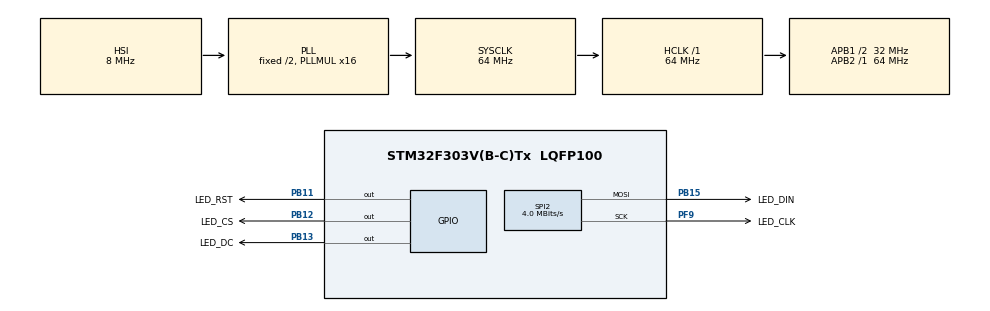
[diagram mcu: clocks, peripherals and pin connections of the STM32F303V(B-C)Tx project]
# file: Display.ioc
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Mcu.Family=STM32F3
Mcu.Name=STM32F303V(B-C)Tx
Mcu.Package=LQFP100
NVIC.PriorityGroup=NVIC_PRIORITYGROUP_4
PB11.GPIO_Label=LED_RST
PB11.Signal=GPIO_Output
PB12.GPIO_Label=LED_CS
PB12.Signal=GPIO_Output
PB13.GPIO_Label=LED_DC
PB13.Signal=GPIO_Output
PB15.GPIO_Label=LED_DIN
PB15.Mode=TX_Only_Simplex_Unidirect_Master
PB15.Signal=SPI2_MOSI
PF9.GPIO_Label=LED_CLK
PF9.Mode=TX_Only_Simplex_Unidirect_Master
PF9.Signal=SPI2_SCK
ProjectManager.HeapSize=0x200
ProjectManager.StackSize=0x400
ProjectManager.TargetToolchain=SW4STM32
RCC.AHBFreq_Value=64000000
RCC.APB1CLKDivider=RCC_HCLK_DIV2
RCC.APB1Freq_Value=32000000
RCC.APB1TimFreq_Value=64000000
RCC.APB2Freq_Value=64000000
RCC.APB2TimFreq_Value=64000000
RCC.CortexFreq_Value=64000000
RCC.HCLKFreq_Value=64000000
RCC.HSE_VALUE=8000000
RCC.HSI_VALUE=8000000
RCC.LSE_VALUE=32768
RCC.PLLMUL=RCC_PLL_MUL16
RCC.SYSCLKFreq_VALUE=64000000
RCC.SYSCLKSourceVirtual=RCC_SYSCLKSOURCE_PLLCLK
RCC.USBFreq_Value=64000000
SPI2.BaudRatePrescaler=SPI_BAUDRATEPRESCALER_8
SPI2.CalculateBaudRate=4.0 MBits/s
SPI2.DataSize=SPI_DATASIZE_8BIT
SPI2.Direction=SPI_DIRECTION_2LINES
SPI2.Mode=SPI_MODE_MASTER
SPI2.VirtualType=VM_MASTER
board=Display

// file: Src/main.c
/**
  ******************************************************************************
  * File Name          : main.c
  * Description        : Main program body
  ******************************************************************************
  ** This notice applies to any and all portions of this file
  * that are not between comment pairs USER CODE BEGIN and
  * USER CODE END. Other portions of this file, whether
  * inserted by the user or by software development tools
  * are owned by their respective copyright owners.
  *
  * COPYRIGHT(c) 2017 STMicroelectronics
  *
  * Redistribution and use in source and binary forms, with or without modification,
  * are permitted provided that the following conditions are met:
  *   1. Redistributions of source code must retain the above copyright notice,
  *      this list of conditions and the following disclaimer.
  *   2. Redistributions in binary form must reproduce the above copyright notice,
  *      this list of conditions and the following disclaimer in the documentation
  *      and/or other materials provided with the distribution.
  *   3. Neither the name of STMicroelectronics nor the names of its contributors
  *      may be used to endorse or promote products derived from this software
  *      without specific prior written permission.
  *
  * THIS SOFTWARE IS PROVIDED BY THE COPYRIGHT HOLDERS AND CONTRIBUTORS "AS IS"
  * AND ANY EXPRESS OR IMPLIED WARRANTIES, INCLUDING, BUT NOT LIMITED TO, THE
  * IMPLIED WARRANTIES OF MERCHANTABILITY AND FITNESS FOR A PARTICULAR PURPOSE ARE
  * DISCLAIMED. IN NO EVENT SHALL THE COPYRIGHT HOLDER OR CONTRIBUTORS BE LIABLE
  * FOR ANY DIRECT, INDIRECT, INCIDENTAL, SPECIAL, EXEMPLARY, OR CONSEQUENTIAL
  * DAMAGES (INCLUDING, BUT NOT LIMITED TO, PROCUREMENT OF SUBSTITUTE GOODS OR
  * SERVICES; LOSS OF USE, DATA, OR PROFITS; OR BUSINESS INTERRUPTION) HOWEVER
  * CAUSED AND ON ANY THEORY OF LIABILITY, WHETHER IN CONTRACT, STRICT LIABILITY,
  * OR TORT (INCLUDING NEGLIGENCE OR OTHERWISE) ARISING IN ANY WAY OUT OF THE USE
  * OF THIS SOFTWARE, EVEN IF ADVISED OF THE POSSIBILITY OF SUCH DAMAGE.
  *
  ******************************************************************************
  */

#include "main.h"
#include "stm32f3xx_hal.h"
#include "spi.h"
#include "gpio.h"
#include "lcd5110.h"

#define LCD_CS_Pin GPIO_PIN_12
#define LCD_CS_GPIO_Port GPIOB
#define LCD_RST_Pin GPIO_PIN_11
#define LCD_RST_GPIO_Port GPIOB
#define LCD_DC_Pin GPIO_PIN_13
#define LCD_DC_GPIO_Port GPIOB

/* USER CODE BEGIN PV */
/* Private variables ---------------------------------------------------------*/

/* USER CODE END PV */

void SystemClock_Config(void);

/* USER CODE BEGIN PFP */
/* Private function prototypes -----------------------------------------------*/

/* USER CODE END PFP */

/* USER CODE BEGIN 0 */
LCD5110_display lcd1;
/* USER CODE END 0 */

void display_on_clock(int hour, int minute, int second, char* weekday, int date, int month, int year){
	LCD5110_clear_scr(&lcd1.hw_conf);
	LCD5110_set_cursor(0,0, &lcd1.hw_conf);
	LCD5110_printf(&lcd1, BLACK, "%i:%i:%i %s %i.%i.%i", hour, minute, second, weekday, date, month, year);
}
int main(void)
{

  /* MCU Configuration----------------------------------------------------------*/

  /* Reset of all peripherals, Initializes the Flash interface and the Systick. */
  HAL_Init();

  /* Configure the system clock */
  SystemClock_Config();

  /* Initialize all configured peripherals */
  MX_GPIO_Init();
  MX_SPI2_Init();

  /* USER CODE BEGIN 2 */
  lcd1.hw_conf.spi_handle = &hspi2;
    lcd1.hw_conf.spi_cs_pin =  LCD_CS_Pin;
    lcd1.hw_conf.spi_cs_port = LCD_CS_GPIO_Port;
    lcd1.hw_conf.rst_pin =  LCD_RST_Pin;
    lcd1.hw_conf.rst_port = LCD_RST_GPIO_Port;
    lcd1.hw_conf.dc_pin =  LCD_DC_Pin;
    lcd1.hw_conf.dc_port = LCD_DC_GPIO_Port;
    lcd1.def_scr = lcd5110_def_scr;
    LCD5110_init(&lcd1.hw_conf, LCD5110_NORMAL_MODE, 0x40, 2, 3);

    // display output
    LCD5110_print("Hello world!\n", BLACK, &lcd1);
    //LCD5110_printf(&lcd1, BLACK, "%i:%i:%i\n", 18, 34, 15);
    //LCD5110_clear_scr(&lcd1.hw_conf);
    //LCD5110_refresh(&lcd1);
    //LCD5110_printf(&lcd1, BLACK, "%i:%i:%i\n", 18, 36, 15);
    /*for (int i=0;i<3;i++){
    	LCD5110_clear_scr(&lcd1.hw_conf);
    	LCD5110_set_cursor(0,0, &lcd1.hw_conf);
    	LCD5110_printf(&lcd1, BLACK, "%i:%i:%i\n", i, i, i);
    }*/

  /* USER CODE END 2 */

  /* Infinite loop */
  while (1)
  {

  }

}

/** System Clock Configuration
*/
void SystemClock_Config(void)
{

  RCC_OscInitTypeDef RCC_OscInitStruct;
  RCC_ClkInitTypeDef RCC_ClkInitStruct;

    /**Initializes the CPU, AHB and APB busses clocks
    */
  RCC_OscInitStruct.OscillatorType = RCC_OSCILLATORTYPE_HSI;
  RCC_OscInitStruct.HSIState = RCC_HSI_ON;
  RCC_OscInitStruct.HSICalibrationValue = 16;
  RCC_OscInitStruct.PLL.PLLState = RCC_PLL_ON;
  RCC_OscInitStruct.PLL.PLLSource = RCC_PLLSOURCE_HSI;
  RCC_OscInitStruct.PLL.PLLMUL = RCC_PLL_MUL16;
  if (HAL_RCC_OscConfig(&RCC_OscInitStruct) != HAL_OK)
  {
    _Error_Handler(__FILE__, __LINE__);
  }

    /**Initializes the CPU, AHB and APB busses clocks
    */
  RCC_ClkInitStruct.ClockType = RCC_CLOCKTYPE_HCLK|RCC_CLOCKTYPE_SYSCLK
                              |RCC_CLOCKTYPE_PCLK1|RCC_CLOCKTYPE_PCLK2;
  RCC_ClkInitStruct.SYSCLKSource = RCC_SYSCLKSOURCE_PLLCLK;
  RCC_ClkInitStruct.AHBCLKDivider = RCC_SYSCLK_DIV1;
  RCC_ClkInitStruct.APB1CLKDivider = RCC_HCLK_DIV2;
  RCC_ClkInitStruct.APB2CLKDivider = RCC_HCLK_DIV1;

  if (HAL_RCC_ClockConfig(&RCC_ClkInitStruct, FLASH_LATENCY_2) != HAL_OK)
  {
    _Error_Handler(__FILE__, __LINE__);
  }

    /**Configure the Systick interrupt time
    */
  HAL_SYSTICK_Config(HAL_RCC_GetHCLKFreq()/1000);

    /**Configure the Systick
    */
  HAL_SYSTICK_CLKSourceConfig(SYSTICK_CLKSOURCE_HCLK);

  /* SysTick_IRQn interrupt configuration */
  HAL_NVIC_SetPriority(SysTick_IRQn, 0, 0);
}

void _Error_Handler(char * file, int line)
{
  while(1)
  {
  }
}

/************************ (C) COPYRIGHT STMicroelectronics *****END OF FILE****/
